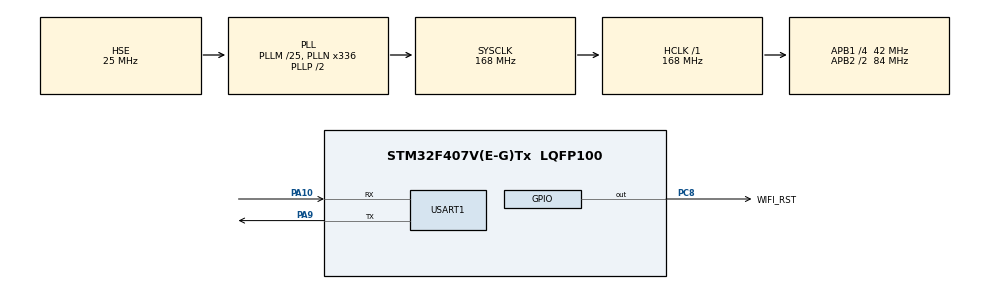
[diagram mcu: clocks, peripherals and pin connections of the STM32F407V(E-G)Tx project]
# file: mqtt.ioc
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Mcu.Family=STM32F4
Mcu.Name=STM32F407V(E-G)Tx
Mcu.Package=LQFP100
NVIC.PriorityGroup=NVIC_PRIORITYGROUP_4
NVIC.USART1_IRQn=true\:3\:0\:true\:false\:true\:true\:true\:true
PA10.Mode=Asynchronous
PA10.Signal=USART1_RX
PA13.Mode=Serial_Wire
PA13.Signal=SYS_JTMS-SWDIO
PA14.Mode=Serial_Wire
PA14.Signal=SYS_JTCK-SWCLK
PA9.Mode=Asynchronous
PA9.Signal=USART1_TX
PC8.GPIO_Label=WIFI_RST
PC8.PinState=GPIO_PIN_SET
PC8.Signal=GPIO_Output
PH0-OSC_IN.Mode=HSE-External-Oscillator
PH0-OSC_IN.Signal=RCC_OSC_IN
PH1-OSC_OUT.Mode=HSE-External-Oscillator
PH1-OSC_OUT.Signal=RCC_OSC_OUT
ProjectManager.HeapSize=0x200
ProjectManager.StackSize=0x400
ProjectManager.TargetToolchain=STM32CubeIDE
RCC.48MHZClocksFreq_Value=84000000
RCC.AHBFreq_Value=168000000
RCC.APB1CLKDivider=RCC_HCLK_DIV4
RCC.APB1Freq_Value=42000000
RCC.APB1TimFreq_Value=84000000
RCC.APB2CLKDivider=RCC_HCLK_DIV2
RCC.APB2Freq_Value=84000000
RCC.APB2TimFreq_Value=168000000
RCC.CortexFreq_Value=168000000
RCC.HCLKFreq_Value=168000000
RCC.HSE_VALUE=25000000
RCC.HSI_VALUE=16000000
RCC.LSE_VALUE=32768
RCC.PLLM=25
RCC.PLLN=336
RCC.PLLSourceVirtual=RCC_PLLSOURCE_HSE
RCC.SYSCLKFreq_VALUE=168000000
RCC.SYSCLKSource=RCC_SYSCLKSOURCE_PLLCLK
RCC.VCOOutputFreq_Value=336000000
USART1.VirtualMode=VM_ASYNC
board=custom

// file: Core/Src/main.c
/* USER CODE BEGIN Header */
/**
  ******************************************************************************
  * @file           : main.c
  * @brief          : Main program body
  ******************************************************************************
  * @attention
  *
  * Copyright (c) 2022 STMicroelectronics.
  * All rights reserved.
  *
  * This software is licensed under terms that can be found in the LICENSE file
  * in the root directory of this software component.
  * If no LICENSE file comes with this software, it is provided AS-IS.
  *
  ******************************************************************************
  */
/* USER CODE END Header */
#include "main.h"
#include "usart.h"
#include "gpio.h"

/* USER CODE BEGIN Includes */
#include "esp8266_at.h"
#include "esp8266_mqtt.h"
#include "stdio.h"
/* USER CODE END Includes */

/* USER CODE BEGIN PD */
#define USER_MAIN_DEBUG

#ifdef USER_MAIN_DEBUG
/*#define user_main_printf(format, ...) printf( format "\r\n",##__VA_ARGS__)
#define user_main_info(format, ...) printf("【main】info:" format "\r\n",##__VA_ARGS__)
#define user_main_debug(format, ...) printf("【main】debug:" format "\r\n",##__VA_ARGS__)
#define user_main_error(format, ...) printf("【main】error:" format "\r\n",##__VA_ARGS__)
#else
#define user_main_printf(format, ...)
#define user_main_info(format, ...)
#define user_main_debug(format, ...)
#define user_main_error(format, ...)*/
#endif
//TP-Link-38DB_5G
//85018433
//Redmi Note 8 Pro
//ujyech4171
// Здесь можно внести коррективы в соответствии с вашим собственным Wi-Fi
#define WIFI_NAME "Redmi Note 8 Pro"
#define WIFI_PASSWD "ujyech4565"

//Вот конфигурация входа в облачный сервер Alibaba Cloud server
#define MQTT_BROKERADDRESS "srv2.clusterfly.ru"
#define MQTT_CLIENTID "user_36de9678_lamp"
#define MQTT_USARNAME "user_36de9678"
#define MQTT_PASSWD "pass_c5048650"
#define	MQTT_PUBLISH_TOPIC "user_36de9678/lamp/power"
#define MQTT_SUBSCRIBE_TOPIC "user_36de9678/lamp/power"

//Вот определение макроса задержки для операции основного цикла
#define LOOPTIME 30 	//Программный цикл время задержки цикла: 30 мс
#define COUNTER_RUNINFOSEND		(5000/LOOPTIME)		//Запрос на запуск последовательного порта: 5s
#define COUNTER_MQTTHEART     (5000/LOOPTIME)		//MQTT отправляет пакет сердцебиения: 5s
#define COUNTER_STATUSREPORT	(3000/LOOPTIME)		//Загрузка статуса: 3 секунды

/* USER CODE END PD */

/* USER CODE BEGIN PV */
char mqtt_message[300];	//Кэш сообщений отчета MQTT
/* USER CODE END PV */

void SystemClock_Config(void);
/* USER CODE BEGIN PFP */
void Enter_ErrorMode(uint8_t mode);
void ES8266_MQTT_Init(void);
void deal_MQTT_message(uint8_t* buf,uint16_t len);
extern void initialise_monitor_handles(void);
/* USER CODE END PFP */

int main(void)
{

  /* MCU Configuration--------------------------------------------------------*/

  /* Reset of all peripherals, Initializes the Flash interface and the Systick. */
  HAL_Init();

  /* USER CODE BEGIN Init */
	initialise_monitor_handles();
	HAL_UART_Receive_IT(&huart1,usart1_rxone,1);			//Откройте прерывание USART1 и получите сообщение о подписке
	ES8266_MQTT_Init();
  /* USER CODE END Init */

  /* Configure the system clock */
  SystemClock_Config();

  /* Initialize all configured peripherals */
  MX_GPIO_Init();
  MX_USART1_UART_Init();

  /* Infinite loop */
  /* USER CODE BEGIN WHILE */
	uint16_t Counter_RUNInfo_Send = 0;
//	uint16_t Counter_MQTT_Heart = 0;
	//uint16_t Counter_StatusReport = 0;
  while (1)
  {
    /* USER CODE END WHILE */

    /* USER CODE BEGIN 3 */
	  if(Counter_RUNInfo_Send++>0)
	  		{
	  			Counter_RUNInfo_Send = 0;
	  			printf("Программа запущена！\r\n");
	  		}
	  		HAL_Delay(LOOPTIME);
  }
  /* USER CODE END 3 */
}

void SystemClock_Config(void)
{
  RCC_OscInitTypeDef RCC_OscInitStruct = {0};
  RCC_ClkInitTypeDef RCC_ClkInitStruct = {0};

  /** Configure the main internal regulator output voltage
  */
  __HAL_RCC_PWR_CLK_ENABLE();
  __HAL_PWR_VOLTAGESCALING_CONFIG(PWR_REGULATOR_VOLTAGE_SCALE1);

  /** Initializes the RCC Oscillators according to the specified parameters
  * in the RCC_OscInitTypeDef structure.
  */
  RCC_OscInitStruct.OscillatorType = RCC_OSCILLATORTYPE_HSE;
  RCC_OscInitStruct.HSEState = RCC_HSE_ON;
  RCC_OscInitStruct.PLL.PLLState = RCC_PLL_ON;
  RCC_OscInitStruct.PLL.PLLSource = RCC_PLLSOURCE_HSE;
  RCC_OscInitStruct.PLL.PLLM = 25;
  RCC_OscInitStruct.PLL.PLLN = 336;
  RCC_OscInitStruct.PLL.PLLP = RCC_PLLP_DIV2;
  RCC_OscInitStruct.PLL.PLLQ = 4;
  if (HAL_RCC_OscConfig(&RCC_OscInitStruct) != HAL_OK)
  {
    Error_Handler();
  }

  /** Initializes the CPU, AHB and APB buses clocks
  */
  RCC_ClkInitStruct.ClockType = RCC_CLOCKTYPE_HCLK|RCC_CLOCKTYPE_SYSCLK
                              |RCC_CLOCKTYPE_PCLK1|RCC_CLOCKTYPE_PCLK2;
  RCC_ClkInitStruct.SYSCLKSource = RCC_SYSCLKSOURCE_PLLCLK;
  RCC_ClkInitStruct.AHBCLKDivider = RCC_SYSCLK_DIV1;
  RCC_ClkInitStruct.APB1CLKDivider = RCC_HCLK_DIV4;
  RCC_ClkInitStruct.APB2CLKDivider = RCC_HCLK_DIV2;

  if (HAL_RCC_ClockConfig(&RCC_ClkInitStruct, FLASH_LATENCY_5) != HAL_OK)
  {
    Error_Handler();
  }
}

/* USER CODE BEGIN 4 */
/******************************  USART1 Код прерывания приема  *****************************/

// ES8266 Последовательный порт привода для приема функции обработки прерываний
void HAL_UART_RxCpltCallback(UART_HandleTypeDef *huart)
{
	if(huart->Instance == USART1)	//Определите, какой последовательный порт вызвал прерывание
	{
		//Поместите полученные данные в принимающий массив usart1 receiving
		usart1_rxbuf[usart1_rxcounter] = usart1_rxone[0];
		usart1_rxcounter++;	//Полученное количество +1

		//Повторно включите последовательный порт 1 для приема прерывания
		HAL_UART_Receive_IT(&huart1,usart1_rxone,1);
	}
}

/******************************  Введите код режима ошибки  *****************************/

//Войдите в режим ошибки и дождитесь ручного перезапуска
void Enter_ErrorMode(uint8_t mode)
{
	while(1)
	{
		switch(mode){
			case 0:printf("ESP8266 Сбой инициализации！\r\n");break;
			case 1:printf("ESP8266 Не удалось подключиться к точке доступа！\r\n");break;
			case 2:printf("ESP8266 Не удалось подключиться к облачному серверу！\r\n");break;
			case 3:printf("ESP8266 Сбой входа в систему Cloud MQTT！\r\n");break;
			case 4:printf("ESP8266 Ошибка в теме подписки на Cloud MQTT не удалась！\r\n");break;
			default:printf("Ничего\r\n");break;
		}
		printf("Пожалуйста, перезапустите совет по разработке\r\n");
		//HAL_GPIO_TogglePin(LED_R_GPIO_Port,LED_R_Pin);
		HAL_Delay(200);
	}
}

/* ESP8266 Тестовый код MQTT */
void TEST_ES8266MQTT(void)
{
	uint8_t status=0;

	//инициализировать
	if(ESP8266_Init())
	{
		printf("ESP8266 Успешная инициализация！\r\n");
		status++;
	}
	else Enter_ErrorMode(0);

	//Подключение к точкам доступа
	if(status==1)
	{
		if(ESP8266_ConnectAP(WIFI_NAME,WIFI_PASSWD))
		{
			printf("ESP8266 Успешно подключился к точке доступа！\r\n");
			status++;
		}
		else Enter_ErrorMode(1);
	}

	//Подключение к облачному серверу интернета вещей
	if(status==2)
	{
		if(ESP8266_ConnectServer("TCP",MQTT_BROKERADDRESS,1883)!=0)
		{
			printf("ESP8266 Успешно подключено к облачному серверу！\r\n");
			status++;
		}
		else Enter_ErrorMode(2);
	}

	if(status==3)
	{
		if(MQTT_Connect(MQTT_CLIENTID, MQTT_USARNAME, MQTT_PASSWD) != 0)
		{
			printf(" Cloud MQTT успешно вошел в систему！\r\n");
			status++;
		}
		else Enter_ErrorMode(3);
	}

	//Подписаться на темы
	if(status==4)
	{
		if(MQTT_SubscribeTopic(MQTT_SUBSCRIBE_TOPIC,0,1) != 0)
		{
			printf("ESP8266 Cloud MQTT успешно подписался на эту тему！\r\n");
		}
		else Enter_ErrorMode(4);
	}
}

/******************************  STM32 MQTT код  *****************************/

//Функция инициализации MQTT
void ES8266_MQTT_Init(void)
{
	uint8_t status=0;

	//Инициализация
	if(ESP8266_Init())
	{
		printf("ESP8266 Успешно！\r\n");
		status++;
	}
	else Enter_ErrorMode(0);

	//Подключение к точкам доступа
	if(status==1)
	{
		if(ESP8266_ConnectAP(WIFI_NAME,WIFI_PASSWD))
		{
			printf("ESP8266 Успешно подключился к точке доступа！\r\n");
			status++;
		}
		else Enter_ErrorMode(1);
	}

	//Подключение к облачному серверу интернета вещей
	if(status==2)
	{
		if(ESP8266_ConnectServer("TCP",MQTT_BROKERADDRESS,9994)!=0)
		{
			printf("ESP8266 Успешно подключено к облачному серверу！\r\n");
			status++;
		}
		else Enter_ErrorMode(2);
	}

	if(status==3)
	{
		if(MQTT_Connect(MQTT_CLIENTID, MQTT_USARNAME, MQTT_PASSWD) != 0)
		{
			printf("ESP8266 Cloud MQTT успешно вошел в систему！\r\n");
			status++;
		}
		else Enter_ErrorMode(3);
	}

	//Подписаться на темы
	if(status==4)
	{
		if(MQTT_SubscribeTopic(MQTT_SUBSCRIBE_TOPIC,0,1) != 0)
		{
			printf("ESP8266 Cloud MQTT успешно подписался на эту тему！\r\n");
		}
		else Enter_ErrorMode(4);
	}
}
/* USER CODE END 4 */

void Error_Handler(void)
{
  __disable_irq();
  while (1)
  {
  }
}
